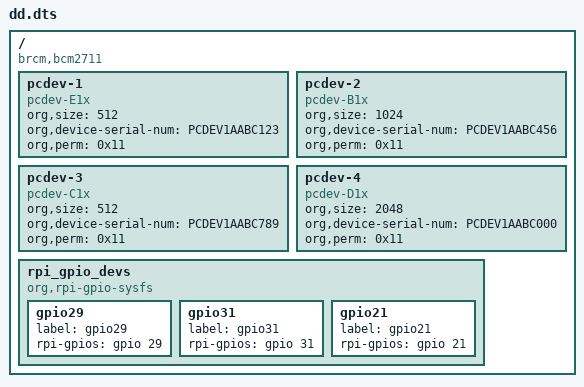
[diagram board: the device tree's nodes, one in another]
/dts-v1/;
/plugin/;

/ {
    compatible = "brcm,bcm2711";
    
    fragment@0 {
        target-path = "/";
        __overlay__ {
            pcdev-1 {
                compatible = "pcdev-E1x", "pcdev-A1x";
                org,size = <512>;
                org,device-serial-num = "PCDEV1AABC123";
                org,perm = <0x11>;
            };
            
            pcdev-2 {
                compatible = "pcdev-B1x";
                org,size = <1024>;
                org,device-serial-num = "PCDEV1AABC456";
                org,perm = <0x11>;
            };
            
            pcdev-3 {
                compatible = "pcdev-C1x";
                org,size = <512>;
                org,device-serial-num = "PCDEV1AABC789";
                org,perm = <0x11>;
            };
            
            pcdev-4 {
                compatible = "pcdev-D1x";
                org,size = <2048>;
                org,device-serial-num = "PCDEV1AABC000";
                org,perm = <0x11>;
            };
            
            rpi_gpio_devs {
                compatible = "org,rpi-gpio-sysfs";
                status = "okay";
                
                gpio29 {
                    label = "gpio29";
                    rpi-gpios = <&gpio 29 0>;
                };
                
                gpio31 {
                    label = "gpio31";
                    rpi-gpios = <&gpio 31 0>;
                };
                
                gpio21 {
                    label = "gpio21";
                    rpi-gpios = <&gpio 21 0>;
                };
            };
        };
    };
};
